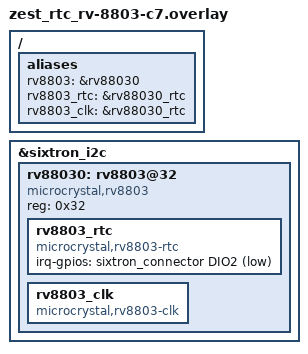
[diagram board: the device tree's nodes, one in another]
/*
 * Copyright (c) 2024, CATIE
 * SPDX-License-Identifier: Apache-2.0
 */

 / {
	aliases {
		rv8803 = &rv88030;
		rv8803_rtc = &rv88030_rtc;
		rv8803_clk = &rv88030_rtc;
	};
};

&sixtron_i2c {
	status = "okay";

	rv88030: rv8803@32 {
		compatible = "microcrystal,rv8803";
		reg = <0x32>;

		rv8803_rtc {
			compatible = "microcrystal,rv8803-rtc";
			irq-gpios = <&sixtron_connector DIO2 (GPIO_ACTIVE_LOW | GPIO_PULL_UP)>;
		};

		rv8803_clk {
			compatible = "microcrystal,rv8803-clk";
			#clock-cells = <0>;
		};
	};
};
